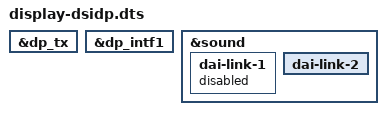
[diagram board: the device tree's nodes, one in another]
/dts-v1/;
/plugin/;

#include "display-dsi.dts"

/ {
	fragment@8 {
		target = <&dp_tx>;
		__overlay__ {
			status = "okay";
		};
	};

	fragment@9 {
		target = <&dp_intf1>;
		__overlay__ {
			status = "okay";
		};
	};

	fragment@10 {
		target = <&sound>;
		__overlay__ {
			dai-link-1 { /* HDMI */
				status = "disabled";
			};

			dai-link-2 { /* DPTX */
				status = "okay";
			};
		};
	};
};
